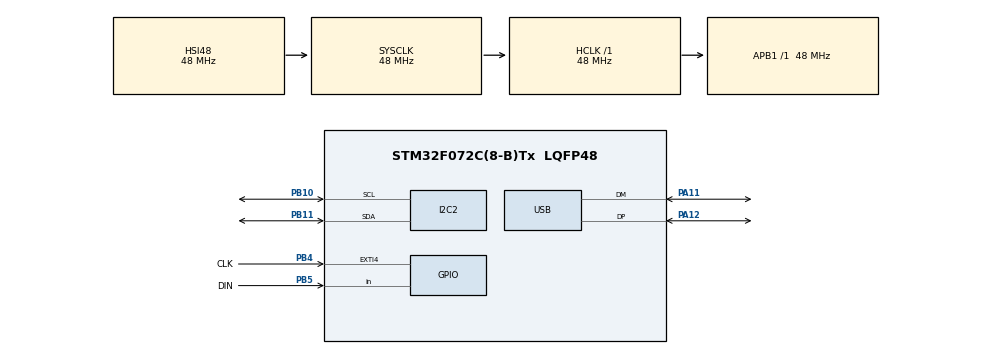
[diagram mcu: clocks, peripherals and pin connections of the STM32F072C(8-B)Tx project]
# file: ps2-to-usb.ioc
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Mcu.Family=STM32F0
Dma.I2C2_TX.1.Direction=DMA_MEMORY_TO_PERIPH
USB_DEVICE.CLASS_NAME_FS=HID
Dma.I2C2_RX.0.MemDataAlignment=DMA_MDATAALIGN_BYTE
NVIC.USB_IRQn=true\:0\:0\:false\:false\:true\:false\:true
PB10.Mode=I2C
USB_DEVICE.VirtualModeFS=Hid_FS
PB4.GPIO_ModeDefaultEXTI=GPIO_MODE_IT_FALLING
Dma.I2C2_RX.0.Priority=DMA_PRIORITY_LOW
I2C2.Timing=0x20303E5D
PA11.Mode=Device
PB11.Signal=I2C2_SDA
RCC.SYSCLKSource=RCC_SYSCLKSOURCE_HSI48
ProjectManager.StackSize=0x400
PA12.Signal=USB_DP
Dma.I2C2_TX.1.Instance=DMA1_Channel4
PB11.Mode=I2C
ProjectManager.TargetToolchain=Makefile
NVIC.I2C2_IRQn=true\:1\:0\:true\:false\:true\:true\:true
RCC.HCLKFreq_Value=48000000
Dma.I2C2_RX.0.PeriphDataAlignment=DMA_PDATAALIGN_BYTE
Dma.I2C2_RX.0.MemInc=DMA_MINC_ENABLE
PB4.GPIO_PuPd=GPIO_PULLUP
RCC.AHBFreq_Value=48000000
PB10.Signal=I2C2_SCL
board=custom
VP_USB_DEVICE_VS_USB_DEVICE_HID_FS.Mode=HID_FS
PB4.GPIO_Label=CLK
NVIC.DMA1_Channel4_5_6_7_IRQn=true\:0\:0\:false\:false\:true\:false\:true
Dma.I2C2_TX.1.MemInc=DMA_MINC_ENABLE
Dma.I2C2_RX.0.Mode=DMA_NORMAL
Dma.I2C2_RX.0.Instance=DMA1_Channel5
Dma.I2C2_RX.0.Direction=DMA_PERIPH_TO_MEMORY
Mcu.Name=STM32F072C(8-B)Tx
Dma.I2C2_RX.0.PeriphInc=DMA_PINC_DISABLE
Dma.I2C2_TX.1.MemDataAlignment=DMA_MDATAALIGN_BYTE
RCC.SYSCLKFreq_VALUE=48000000
Mcu.Package=LQFP48
PB5.Signal=GPIO_Input
PA12.Mode=Device
Dma.I2C2_TX.1.PeriphDataAlignment=DMA_PDATAALIGN_BYTE
PB5.GPIO_PuPd=GPIO_PULLUP
PA11.Signal=USB_DM
ProjectManager.HeapSize=0x200
Dma.I2C2_TX.1.PeriphInc=DMA_PINC_DISABLE
PB5.GPIO_Label=DIN
Dma.Request1=I2C2_TX
RCC.APB1TimFreq_Value=48000000
Dma.I2C2_TX.1.Priority=DMA_PRIORITY_LOW
Dma.Request0=I2C2_RX
RCC.APB1Freq_Value=48000000
USB_DEVICE.VirtualMode=Hid
Dma.I2C2_TX.1.Mode=DMA_NORMAL
NVIC.EXTI4_15_IRQn=true\:0\:0\:false\:false\:true\:true\:true
PB4.Signal=GPXTI4

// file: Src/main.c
/* USER CODE BEGIN Header */
/**
  ******************************************************************************
  * @file           : main.c
  * @brief          : Main program body
  ******************************************************************************
  * @attention
  *
  * <h2><center>&copy; Copyright (c) 2020 STMicroelectronics.
  * All rights reserved.</center></h2>
  *
  * This software component is licensed by ST under Ultimate Liberty license
  * SLA0044, the "License"; You may not use this file except in compliance with
  * the License. You may obtain a copy of the License at:
  *                             www.st.com/SLA0044
  *
  ******************************************************************************
  */
/* USER CODE END Header */
#include "main.h"
#include "dma.h"
#include "i2c.h"
#include "usb_device.h"
#include "gpio.h"

/* USER CODE BEGIN Includes */

#include <stdbool.h>

#include "usbd_hid.h"

#include "keyboard.h"
#include "queue.h"

/* USER CODE END Includes */

/* USER CODE BEGIN PV */

extern USBD_HandleTypeDef hUsbDeviceFS;

struct queue_t keyq = {0};
struct keyboard_hid_t khid = {0};
uint32_t keyq_timeout = 0;

/* USER CODE END PV */

void SystemClock_Config(void);
/* USER CODE BEGIN PFP */

void HAL_GPIO_EXTI_Callback(uint16_t pin);

/* USER CODE END PFP */

int main(void)
{

  /* MCU Configuration--------------------------------------------------------*/

  /* Reset of all peripherals, Initializes the Flash interface and the Systick. */
  HAL_Init();

  /* Configure the system clock */
  SystemClock_Config();

  /* Initialize all configured peripherals */
  MX_GPIO_Init();
  MX_DMA_Init();
  MX_USB_DEVICE_Init();
  MX_I2C2_Init();
  /* USER CODE BEGIN 2 */

  queue_init(&keyq);

  /* USER CODE END 2 */

  /* Infinite loop */
  /* USER CODE BEGIN WHILE */
  while (1)
  {
    handle_keys(&hUsbDeviceFS, &khid, &keyq, keyq_timeout, &hi2c2);
    /* USER CODE END WHILE */

  }
}

void SystemClock_Config(void)
{
  RCC_OscInitTypeDef RCC_OscInitStruct = {0};
  RCC_ClkInitTypeDef RCC_ClkInitStruct = {0};
  RCC_PeriphCLKInitTypeDef PeriphClkInit = {0};

  /** Initializes the RCC Oscillators according to the specified parameters
  * in the RCC_OscInitTypeDef structure.
  */
  RCC_OscInitStruct.OscillatorType = RCC_OSCILLATORTYPE_HSI48;
  RCC_OscInitStruct.HSI48State = RCC_HSI48_ON;
  RCC_OscInitStruct.PLL.PLLState = RCC_PLL_NONE;
  if (HAL_RCC_OscConfig(&RCC_OscInitStruct) != HAL_OK)
  {
    Error_Handler();
  }
  /** Initializes the CPU, AHB and APB buses clocks
  */
  RCC_ClkInitStruct.ClockType = RCC_CLOCKTYPE_HCLK|RCC_CLOCKTYPE_SYSCLK
                              |RCC_CLOCKTYPE_PCLK1;
  RCC_ClkInitStruct.SYSCLKSource = RCC_SYSCLKSOURCE_HSI48;
  RCC_ClkInitStruct.AHBCLKDivider = RCC_SYSCLK_DIV1;
  RCC_ClkInitStruct.APB1CLKDivider = RCC_HCLK_DIV1;

  if (HAL_RCC_ClockConfig(&RCC_ClkInitStruct, FLASH_LATENCY_1) != HAL_OK)
  {
    Error_Handler();
  }
  PeriphClkInit.PeriphClockSelection = RCC_PERIPHCLK_USB;
  PeriphClkInit.UsbClockSelection = RCC_USBCLKSOURCE_HSI48;

  if (HAL_RCCEx_PeriphCLKConfig(&PeriphClkInit) != HAL_OK)
  {
    Error_Handler();
  }
}

/* USER CODE BEGIN 4 */

void HAL_GPIO_EXTI_Callback(uint16_t pin)
{
  if (pin == CLK_Pin)
  {
    ps2_clk_callback(&keyq, &keyq_timeout, DIN_GPIO_Port, DIN_Pin);
  }
}

/* USER CODE END 4 */

void Error_Handler(void)
{
}

/************************ (C) COPYRIGHT STMicroelectronics *****END OF FILE****/
